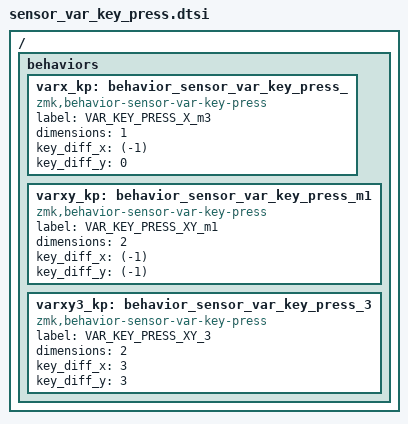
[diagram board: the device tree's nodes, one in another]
/*
 * Copyright (c) 2020 The ZMK Contributors
 *
 * SPDX-License-Identifier: MIT
 */

/ {
	behaviors {
		/omit-if-no-ref/ varx_kp: behavior_sensor_var_key_press_ {
			compatible = "zmk,behavior-sensor-var-key-press";
			label = "VAR_KEY_PRESS_X_m3";
			dimensions = <1>;
			key_diff_x = < (-1) >;
			key_diff_y = <0>;
			#sensor-binding-cells = <1>;
		};
		/omit-if-no-ref/ varxy_kp: behavior_sensor_var_key_press_m1 {
			compatible = "zmk,behavior-sensor-var-key-press";
			label = "VAR_KEY_PRESS_XY_m1";
			dimensions = <2>;
			key_diff_x = < (-1) >;
			key_diff_y = < (-1) >;
			#sensor-binding-cells = <2>;
		};
		/omit-if-no-ref/ varxy3_kp: behavior_sensor_var_key_press_3 {
			compatible = "zmk,behavior-sensor-var-key-press";
			label = "VAR_KEY_PRESS_XY_3";
			dimensions = <2>;
			key_diff_x = < 3 >;
			key_diff_y = < 3 >;
			#sensor-binding-cells = <2>;
		};
	};
};
